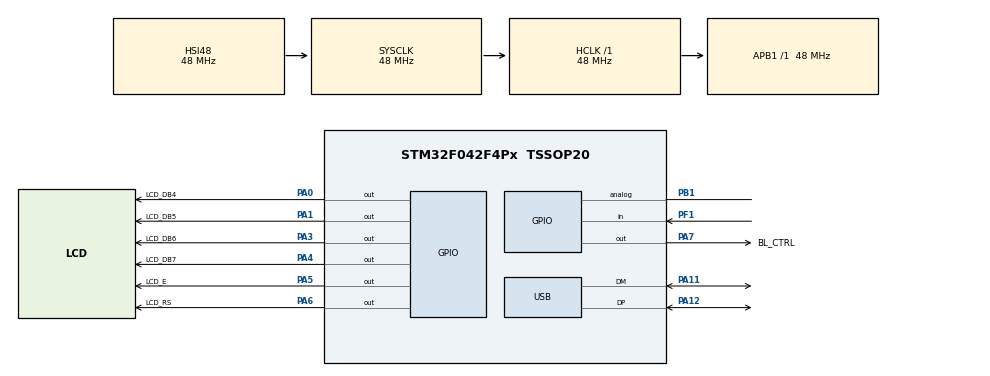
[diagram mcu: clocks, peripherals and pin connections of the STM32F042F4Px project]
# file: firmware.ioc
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Mcu.Family=STM32F0
Mcu.Name=STM32F042F4Px
Mcu.Package=TSSOP20
NVIC.TIM17_IRQn=true\:3\:0\:false\:false\:true\:false\:true\:true
NVIC.TimeBase=TIM17_IRQn
NVIC.TimeBaseIP=TIM17
PA0.GPIO_Label=LCD_DB4
PA0.Signal=GPIO_Output
PA1.GPIO_Label=LCD_DB5
PA1.Signal=GPIO_Output
PA11.Mode=Device
PA11.Signal=USB_DM
PA12.Mode=Device
PA12.Signal=USB_DP
PA13.Mode=Serial_Wire
PA13.Signal=SYS_SWDIO
PA14.Mode=Serial_Wire
PA14.Signal=SYS_SWCLK
PA2.Signal=USART2_TX
PA3.GPIO_Label=LCD_DB6
PA3.Signal=GPIO_Output
PA4.GPIO_Label=LCD_DB7
PA4.Signal=GPIO_Output
PA5.GPIO_Label=LCD_E
PA5.Signal=GPIO_Output
PA6.GPIO_Label=LCD_RS
PA6.Signal=GPIO_Output
PA7.GPIO_Label=BL_CTRL
PA7.Signal=GPIO_Output
PB1.Signal=GPIO_Analog
PF1-OSC_OUT.Signal=GPIO_Input
ProjectManager.HeapSize=0x100
ProjectManager.StackSize=0x200
ProjectManager.TargetToolchain=Makefile
RCC.AHBFreq_Value=48000000
RCC.APB1Freq_Value=48000000
RCC.APB1TimFreq_Value=48000000
RCC.HCLKFreq_Value=48000000
RCC.SYSCLKFreq_VALUE=48000000
RCC.SYSCLKSource=RCC_SYSCLKSOURCE_HSI48
VP_SYS_VS_PINREMAP.Mode=PINREMAP
VP_SYS_VS_tim17.Mode=TIM17
board=custom

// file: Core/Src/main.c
/* USER CODE BEGIN Header */
/**
  ******************************************************************************
  * @file           : main.c
  * @brief          : Main program body
  ******************************************************************************
  * @attention
  *
  * Copyright (c) 2022 STMicroelectronics.
  * All rights reserved.
  *
  * This software is licensed under terms that can be found in the LICENSE file
  * in the root directory of this software component.
  * If no LICENSE file comes with this software, it is provided AS-IS.
  *
  ******************************************************************************
  */
/* USER CODE END Header */
#include "main.h"

 PCD_HandleTypeDef hpcd_USB_FS;

void SystemClock_Config(void);
static void MX_GPIO_Init(void);
static void MX_USB_PCD_Init(void);

int main(void)
{

  /* MCU Configuration--------------------------------------------------------*/

  /* Reset of all peripherals, Initializes the Flash interface and the Systick. */
  HAL_Init();

  /* Configure the system clock */
  SystemClock_Config();

  /* Initialize all configured peripherals */
  MX_GPIO_Init();
  MX_USB_PCD_Init();
  /* USER CODE BEGIN 2 */
  LCD_Init();
  /* USER CODE END 2 */

  /* Infinite loop */
  while (1)
  {
    LCD_Cls();
	  LCD_Locate(0,0);
	  LCD_String(" STM32 + HD44780");
	  LCD_Locate(0,1);
	  LCD_String("www.msalamon.pl ");
	  // Measurement end
	  // HAL_GPIO_TogglePin(LED_GPIO_Port, LED_Pin);
	  HAL_Delay(500);
  }
}

void SystemClock_Config(void)
{
  RCC_OscInitTypeDef RCC_OscInitStruct = {0};
  RCC_ClkInitTypeDef RCC_ClkInitStruct = {0};
  RCC_PeriphCLKInitTypeDef PeriphClkInit = {0};

  /** Initializes the RCC Oscillators according to the specified parameters
  * in the RCC_OscInitTypeDef structure.
  */
  RCC_OscInitStruct.OscillatorType = RCC_OSCILLATORTYPE_HSI48;
  RCC_OscInitStruct.HSI48State = RCC_HSI48_ON;
  RCC_OscInitStruct.PLL.PLLState = RCC_PLL_NONE;
  if (HAL_RCC_OscConfig(&RCC_OscInitStruct) != HAL_OK)
  {
    Error_Handler();
  }

  /** Initializes the CPU, AHB and APB buses clocks
  */
  RCC_ClkInitStruct.ClockType = RCC_CLOCKTYPE_HCLK|RCC_CLOCKTYPE_SYSCLK
                              |RCC_CLOCKTYPE_PCLK1;
  RCC_ClkInitStruct.SYSCLKSource = RCC_SYSCLKSOURCE_HSI48;
  RCC_ClkInitStruct.AHBCLKDivider = RCC_SYSCLK_DIV1;
  RCC_ClkInitStruct.APB1CLKDivider = RCC_HCLK_DIV1;

  if (HAL_RCC_ClockConfig(&RCC_ClkInitStruct, FLASH_LATENCY_1) != HAL_OK)
  {
    Error_Handler();
  }
  PeriphClkInit.PeriphClockSelection = RCC_PERIPHCLK_USB;
  PeriphClkInit.UsbClockSelection = RCC_USBCLKSOURCE_HSI48;

  if (HAL_RCCEx_PeriphCLKConfig(&PeriphClkInit) != HAL_OK)
  {
    Error_Handler();
  }
}

static void MX_USB_PCD_Init(void)
{

  hpcd_USB_FS.Instance = USB;
  hpcd_USB_FS.Init.dev_endpoints = 8;
  hpcd_USB_FS.Init.speed = PCD_SPEED_FULL;
  hpcd_USB_FS.Init.phy_itface = PCD_PHY_EMBEDDED;
  hpcd_USB_FS.Init.low_power_enable = DISABLE;
  hpcd_USB_FS.Init.lpm_enable = DISABLE;
  hpcd_USB_FS.Init.battery_charging_enable = DISABLE;
  if (HAL_PCD_Init(&hpcd_USB_FS) != HAL_OK)
  {
    Error_Handler();
  }

}

static void MX_GPIO_Init(void)
{
  GPIO_InitTypeDef GPIO_InitStruct = {0};

  /* GPIO Ports Clock Enable */
  __HAL_RCC_GPIOF_CLK_ENABLE();
  __HAL_RCC_GPIOA_CLK_ENABLE();
  __HAL_RCC_GPIOB_CLK_ENABLE();

  /*Configure GPIO pin Output Level */
  HAL_GPIO_WritePin(GPIOA, GPIO_PIN_0|GPIO_PIN_1|GPIO_PIN_3|GPIO_PIN_4
                          |GPIO_PIN_5|GPIO_PIN_6|GPIO_PIN_7, GPIO_PIN_RESET);

  /*Configure GPIO pin : PF1 */
  GPIO_InitStruct.Pin = GPIO_PIN_1;
  GPIO_InitStruct.Mode = GPIO_MODE_INPUT;
  GPIO_InitStruct.Pull = GPIO_NOPULL;
  HAL_GPIO_Init(GPIOF, &GPIO_InitStruct);

  /*Configure GPIO pins : PA0 PA1 PA3 PA4
                           PA5 PA6 PA7 */
  GPIO_InitStruct.Pin = GPIO_PIN_0|GPIO_PIN_1|GPIO_PIN_3|GPIO_PIN_4
                          |GPIO_PIN_5|GPIO_PIN_6|GPIO_PIN_7;
  GPIO_InitStruct.Mode = GPIO_MODE_OUTPUT_PP;
  GPIO_InitStruct.Pull = GPIO_NOPULL;
  GPIO_InitStruct.Speed = GPIO_SPEED_FREQ_LOW;
  HAL_GPIO_Init(GPIOA, &GPIO_InitStruct);

  /*Configure GPIO pin : PA2 */
  GPIO_InitStruct.Pin = GPIO_PIN_2;
  GPIO_InitStruct.Mode = GPIO_MODE_AF_PP;
  GPIO_InitStruct.Pull = GPIO_NOPULL;
  GPIO_InitStruct.Speed = GPIO_SPEED_FREQ_HIGH;
  GPIO_InitStruct.Alternate = GPIO_AF1_USART2;
  HAL_GPIO_Init(GPIOA, &GPIO_InitStruct);

  /*Configure GPIO pin : PB1 */
  GPIO_InitStruct.Pin = GPIO_PIN_1;
  GPIO_InitStruct.Mode = GPIO_MODE_ANALOG;
  GPIO_InitStruct.Pull = GPIO_NOPULL;
  HAL_GPIO_Init(GPIOB, &GPIO_InitStruct);

}

void HAL_TIM_PeriodElapsedCallback(TIM_HandleTypeDef *htim)
{
  if (htim->Instance == TIM17) {
    HAL_IncTick();
  }
}

void Error_Handler(void)
{
  __disable_irq();
  while (1)
  {
  }
}
